VERSION ""

NS_ :

BS_:

BU_:

BO_ 950 ID3B6odometer: 4 Vector__XXX
 SG_ Odometer3B6 : 7|32@0+ (1,0) [0|4294967295] "Meter" Vector__XXX

BO_ 614 ID266: 8 Vector__XXX
 SG_ v12vInverter266 : 0|8@1+ (0.1,0) [0|0] "Volts" Vector__XXX

BO_ 264 ID108: 8 Vector__XXX
 SG_ RPMspeed108 : 40|16@1- (0.0078125,0) [0|0] "MPH" Vector__XXX

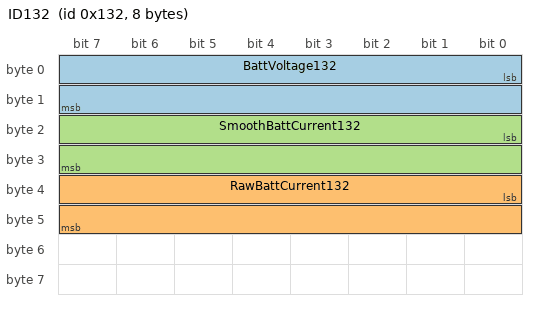
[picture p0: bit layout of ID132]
BO_ 306 ID132: 8 Vector__XXX
 SG_ BattVoltage132 : 0|16@1+ (0.01,0) [0|0] "Volts" Vector__XXX
 SG_ RawBattCurrent132 : 32|16@1+ (-0.1,-20000) [0|0] "Amps" Vector__XXX
 SG_ SmoothBattCurrent132 : 16|16@1+ (-0.2,-10000) [0|0] "Amps" Vector__XXX

BO_ 294 ID126: 8 Vector__XXX
 SG_ Demand126 : 16|16@1+ (1,0) [0|0] "" Vector__XXX
 SG_ BattVoltage126 : 0|16@1+ (0.5,0) [0|32767.5] "Volts" Vector__XXX
